AUTOSAR XML (schema 4-2-2)
package /ComponentTypes
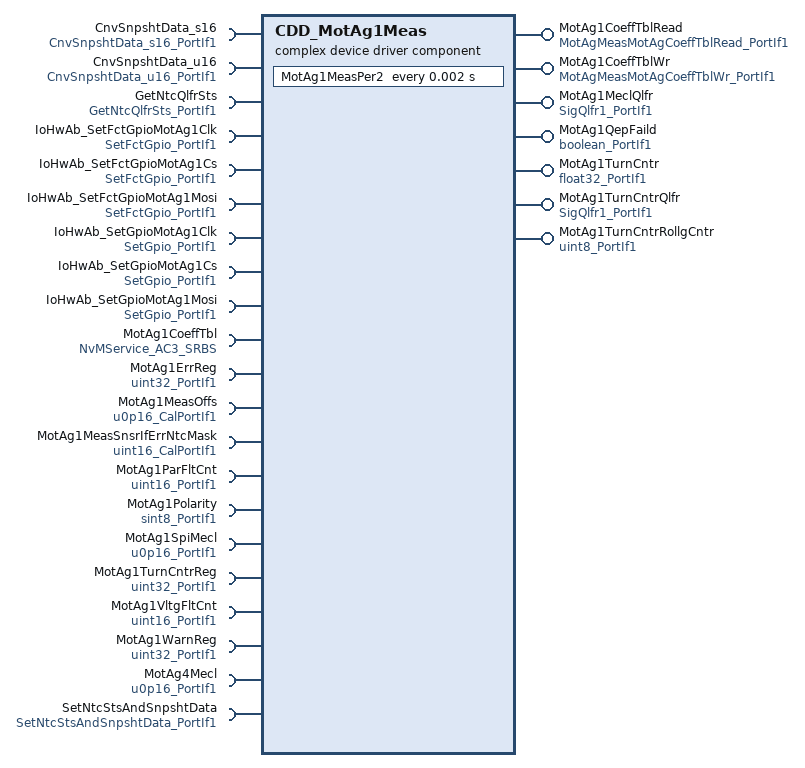
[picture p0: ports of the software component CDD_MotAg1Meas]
  complex device driver sw component type CDD_MotAg1Meas
    7 x provide port:
      MotAg1CoeffTblRead: server-com-spec{operation=Oper, queue-length=1}, provided-interface=MotAgMeasMotAgCoeffTblRead_PortIf1
      MotAg1CoeffTblWr: server-com-spec{operation=Oper, queue-length=1}, provided-interface=MotAgMeasMotAgCoeffTblWr_PortIf1
      MotAg1MeclQlfr: nonqueued-sender-com-spec{data-element=Val, init-value=0}, provided-interface=SigQlfr1_PortIf1
      MotAg1QepFaild: nonqueued-sender-com-spec{data-element=Logl, init-value=0}, provided-interface=boolean_PortIf1
      MotAg1TurnCntr: nonqueued-sender-com-spec{data-element=Val, init-value=0}, provided-interface=float32_PortIf1
      MotAg1TurnCntrQlfr: nonqueued-sender-com-spec{data-element=Val, init-value=0}, provided-interface=SigQlfr1_PortIf1
      MotAg1TurnCntrRollgCntr: nonqueued-sender-com-spec{data-element=Val, init-value=0}, provided-interface=uint8_PortIf1
    21 x require port:
      CnvSnpshtData_s16: client-com-spec=Oper, required-interface=CnvSnpshtData_s16_PortIf1
      CnvSnpshtData_u16: client-com-spec=Oper, required-interface=CnvSnpshtData_u16_PortIf1
      GetNtcQlfrSts: client-com-spec=Oper, required-interface=GetNtcQlfrSts_PortIf1
      IoHwAb_SetFctGpioMotAg1Clk: client-com-spec=Oper, required-interface=SetFctGpio_PortIf1
      IoHwAb_SetFctGpioMotAg1Cs: client-com-spec=Oper, required-interface=SetFctGpio_PortIf1
      IoHwAb_SetFctGpioMotAg1Mosi: client-com-spec=Oper, required-interface=SetFctGpio_PortIf1
      IoHwAb_SetGpioMotAg1Clk: client-com-spec=Oper, required-interface=SetGpio_PortIf1
      IoHwAb_SetGpioMotAg1Cs: client-com-spec=Oper, required-interface=SetGpio_PortIf1
      IoHwAb_SetGpioMotAg1Mosi: client-com-spec=Oper, required-interface=SetGpio_PortIf1
      MotAg1CoeffTbl: required-com-specs=[EraseBlock, GetErrorStatus, InvalidateNvBlock, ReadBlock, SetRamBlockStatus, WriteBlock], required-interface=NvMService_AC3_SRBS
      MotAg1ErrReg: nonqueued-receiver-com-spec{data-element=Val, filter=data-filter-type=ALWAYS, init-value=0}, required-interface=uint32_PortIf1
      MotAg1MeasOffs: parameter-require-com-spec{init-value=32768, parameter=Val}, required-interface=u0p16_CalPortIf1
      MotAg1MeasSnsrIfErrNtcMask: parameter-require-com-spec{init-value=512, parameter=Val}, required-interface=uint16_CalPortIf1
      MotAg1ParFltCnt: nonqueued-receiver-com-spec{data-element=Val, filter=data-filter-type=ALWAYS, init-value=0}, required-interface=uint16_PortIf1
      MotAg1Polarity: nonqueued-receiver-com-spec{data-element=Val, filter=data-filter-type=ALWAYS, init-value=1}, required-interface=sint8_PortIf1
      MotAg1SpiMecl: nonqueued-receiver-com-spec{data-element=Val, filter=data-filter-type=ALWAYS, init-value=0}, required-interface=u0p16_PortIf1
      MotAg1TurnCntrReg: nonqueued-receiver-com-spec{data-element=Val, filter=data-filter-type=ALWAYS, init-value=0}, required-interface=uint32_PortIf1
      MotAg1VltgFltCnt: nonqueued-receiver-com-spec{data-element=Val, filter=data-filter-type=ALWAYS, init-value=0}, required-interface=uint16_PortIf1
      MotAg1WarnReg: nonqueued-receiver-com-spec{data-element=Val, filter=data-filter-type=ALWAYS, init-value=0}, required-interface=uint32_PortIf1
      MotAg4Mecl: nonqueued-receiver-com-spec{data-element=Val, filter=data-filter-type=ALWAYS, init-value=0}, required-interface=u0p16_PortIf1
      SetNtcStsAndSnpshtData: client-com-spec=Oper, required-interface=SetNtcStsAndSnpshtData_PortIf1
    behavior CDD_MotAg1Meas_InternalBehavior
      ar-typed-per-instance-memorys:
        27 x data, all with sw-calibration-access=READ-ONLY:
          dMotAg1MeasMotAg1Delta: type=u0p16  # Display variable holding difference between angle from QEP interface and angle from SPI bus
          dMotAg1MeasMotAg1RawAgReg: type=uint32  # Display variable for Motor Angle 1 Raw Angle Register
          dMotAg1MeasMotAg1RawErrReg: type=uint32  # Display variable for Motor Angle 1 Raw Error Register
          dMotAg1MeasMotAg1RawStsReg: type=uint32  # Display variable for Motor Angle 1 Raw status Register
          dMotAg1MeasMotAg1RawTurnCntrReg: type=uint32  # Display variable Motor Angle 1 Raw Turn Counter Register
          dMotAg1MeasMotAg1RawWarnReg: type=uint32  # Display variable for Motor Angle 1 Raw warning Register
          dMotAg1MeasMotAg1RtOffs: type=uint16  # Display variable of Motor Angle 1 Runtime Offset
          dMotAg1MeasPwrRstStsLtch: type=boolean
          MotAg1CoeffTbl: type=Ary1D_f32_26
          MotAg1CorrnTbl: type=Ary1D_sm5p12_128
          MotAg1InitOffs: type=sint32
          MotAg1InitOffsCntr: type=uint8
          MotAg1MeclRollgCntrPrev: type=uint8
          MotAg1ParFltCntNtcPrev: type=uint16
          MotAg1ParFltCntPrev: type=uint16
          MotAg1PrevSpiMecl: type=u0p16
          MotAg1PrevTCUpd: type=sint16
          MotAg1QepFaildCntr: type=uint32
          MotAg1QepFaildPrev: type=boolean
          MotAg1RawMeclPrev: type=u0p16
          MotAg1TurnCntrParFltCntNtcPrev: type=uint16
          MotAg1TurnCntrParFltCntPrev: type=uint16
          MotAg1TurnCntrPrev: type=sint16
          MotAg1TurnCntrRollgCntrPrev: type=uint8
          MotAg1VltgFltCntNtcPrev: type=uint16
          MotAg1VltgFltCntPrev: type=uint16
          MotAgMecl1Polarity: type=sint8
      operation invoked event OIT_MotAg1CoeffTblRead_Oper_MotAg1CoeffTblRead_Oper: start-on-event=MotAg1CoeffTblRead_Oper, operation=MotAg1CoeffTblRead.Oper
      operation invoked event OIT_MotAg1CoeffTblWr_Oper_MotAg1CoeffTblWr_Oper: start-on-event=MotAg1CoeffTblWr_Oper, operation=MotAg1CoeffTblWr.Oper
      init event CDD_MotAg1Meas_InitEvent: start-on-event=MotAg1MeasInit1
      timing event TMT_MotAg1MeasPer2: start-on-event=MotAg1MeasPer2, period=0.002
      port-api-options:
        enable-take-address=false, error-handling=NO-TRANSFORMER-ERROR-HANDLING, indirect-api=false, port=CnvSnpshtData_s16
        enable-take-address=false, error-handling=NO-TRANSFORMER-ERROR-HANDLING, indirect-api=false, port=CnvSnpshtData_u16
        enable-take-address=false, error-handling=NO-TRANSFORMER-ERROR-HANDLING, indirect-api=false, port=GetNtcQlfrSts
        enable-take-address=false, error-handling=NO-TRANSFORMER-ERROR-HANDLING, indirect-api=false, port=MotAg1CoeffTbl
        enable-take-address=false, error-handling=NO-TRANSFORMER-ERROR-HANDLING, indirect-api=false, port=MotAg1CoeffTblRead
        enable-take-address=false, error-handling=NO-TRANSFORMER-ERROR-HANDLING, indirect-api=false, port=MotAg1CoeffTblWr
        enable-take-address=false, error-handling=NO-TRANSFORMER-ERROR-HANDLING, indirect-api=false, port=MotAg1ErrReg
        enable-take-address=false, error-handling=NO-TRANSFORMER-ERROR-HANDLING, indirect-api=false, port=MotAg1MeasOffs
        enable-take-address=false, error-handling=NO-TRANSFORMER-ERROR-HANDLING, indirect-api=false, port=MotAg1MeasSnsrIfErrNtcMask
        enable-take-address=false, error-handling=NO-TRANSFORMER-ERROR-HANDLING, indirect-api=false, port=MotAg1MeclQlfr
        enable-take-address=false, error-handling=NO-TRANSFORMER-ERROR-HANDLING, indirect-api=false, port=MotAg1ParFltCnt
        enable-take-address=false, error-handling=NO-TRANSFORMER-ERROR-HANDLING, indirect-api=false, port=MotAg1Polarity
        enable-take-address=false, error-handling=NO-TRANSFORMER-ERROR-HANDLING, indirect-api=false, port=MotAg1QepFaild
        enable-take-address=false, error-handling=NO-TRANSFORMER-ERROR-HANDLING, indirect-api=false, port=MotAg1SpiMecl
        enable-take-address=false, error-handling=NO-TRANSFORMER-ERROR-HANDLING, indirect-api=false, port=MotAg1TurnCntr
        enable-take-address=false, error-handling=NO-TRANSFORMER-ERROR-HANDLING, indirect-api=false, port=MotAg1TurnCntrQlfr
        enable-take-address=false, error-handling=NO-TRANSFORMER-ERROR-HANDLING, indirect-api=false, port=MotAg1TurnCntrReg
        enable-take-address=false, error-handling=NO-TRANSFORMER-ERROR-HANDLING, indirect-api=false, port=MotAg1TurnCntrRollgCntr
        enable-take-address=false, error-handling=NO-TRANSFORMER-ERROR-HANDLING, indirect-api=false, port=MotAg1VltgFltCnt
        enable-take-address=false, error-handling=NO-TRANSFORMER-ERROR-HANDLING, indirect-api=false, port=MotAg1WarnReg
        enable-take-address=false, error-handling=NO-TRANSFORMER-ERROR-HANDLING, indirect-api=false, port=MotAg4Mecl
        enable-take-address=false, error-handling=NO-TRANSFORMER-ERROR-HANDLING, indirect-api=false, port=SetNtcStsAndSnpshtData
      4 x runnable:
        MotAg1CoeffTblRead_Oper
        MotAg1CoeffTblWr_Oper
          sync call SC_MotAg1CoeffTbl_SetRamBlockStatus: operation=MotAg1CoeffTbl.SetRamBlockStatus, timeout=0
        MotAg1MeasInit1
          data-receive-point-by-arguments:
            access REC_MotAg1Polarity_Val: accessed-variable=MotAg1Polarity.Val
          7 x sync call, all with timeout=0:
            SC_IoHwAb_SetFctGpioMotAg1Clk_Oper: operation=IoHwAb_SetFctGpioMotAg1Clk.Oper
            SC_IoHwAb_SetFctGpioMotAg1Cs_Oper: operation=IoHwAb_SetFctGpioMotAg1Cs.Oper
            SC_IoHwAb_SetFctGpioMotAg1Mosi_Oper: operation=IoHwAb_SetFctGpioMotAg1Mosi.Oper
            SC_IoHwAb_SetGpioMotAg1Clk_Oper: operation=IoHwAb_SetGpioMotAg1Clk.Oper
            SC_IoHwAb_SetGpioMotAg1Cs_Oper: operation=IoHwAb_SetGpioMotAg1Cs.Oper
            SC_IoHwAb_SetGpioMotAg1Mosi_Oper: operation=IoHwAb_SetGpioMotAg1Mosi.Oper
            SC_MotAg1CoeffTbl_GetErrorStatus: operation=MotAg1CoeffTbl.GetErrorStatus
        MotAg1MeasPer2
          data-receive-point-by-arguments:
            8 x access:
              REC_MotAg1ErrReg_Val: accessed-variable=MotAg1ErrReg.Val
              REC_MotAg1ParFltCnt_Val: accessed-variable=MotAg1ParFltCnt.Val
              REC_MotAg1Polarity_Val: accessed-variable=MotAg1Polarity.Val
              REC_MotAg1SpiMecl_Val: accessed-variable=MotAg1SpiMecl.Val
              REC_MotAg1TurnCntrReg_Val: accessed-variable=MotAg1TurnCntrReg.Val
              REC_MotAg1VltgFltCnt_Val: accessed-variable=MotAg1VltgFltCnt.Val
              REC_MotAg1WarnReg_Val: accessed-variable=MotAg1WarnReg.Val
              REC_MotAg4Mecl_Val: accessed-variable=MotAg4Mecl.Val
          data-send-points:
            5 x access:
              SEND_MotAg1MeclQlfr_Val: accessed-variable=MotAg1MeclQlfr.Val
              SEND_MotAg1QepFaild_Logl: accessed-variable=MotAg1QepFaild.Logl
              SEND_MotAg1TurnCntr_Val: accessed-variable=MotAg1TurnCntr.Val
              SEND_MotAg1TurnCntrQlfr_Val: accessed-variable=MotAg1TurnCntrQlfr.Val
              SEND_MotAg1TurnCntrRollgCntr_Val: accessed-variable=MotAg1TurnCntrRollgCntr.Val
          4 x sync call, all with timeout=0:
            SC_CnvSnpshtData_s16_Oper: operation=CnvSnpshtData_s16.Oper
            SC_CnvSnpshtData_u16_Oper: operation=CnvSnpshtData_u16.Oper
            SC_GetNtcQlfrSts_Oper: operation=GetNtcQlfrSts.Oper
            SC_SetNtcStsAndSnpshtData_Oper: operation=SetNtcStsAndSnpshtData.Oper
      swc service dependency NvmMotAg1CoeffTbl: assigned-datas=role-based-data-assignment={role=ramBlock, used-data-element=MotAg1CoeffTbl}, assigned-ports=role-based-port-assignment={port-prototype=MotAg1CoeffTbl, role=NvMService_AC3_SRBS}
        service-needs:
          nv block needs NvmMotAg1CoeffTbl: n-data-sets=0, ram-block-status-control=API, readonly=false, reliability=ERROR-DETECTION, resistant-to-changed-sw=true, restore-at-start=true, store-at-shutdown=true, write-only-once=false, writing-frequency=0, writing-priority=LOW
      shared-parameters:
        parameter data prototype MotAg1CoeffTblDft: sw-calibration-access=READ-WRITE, type=Ary1D_f32_26, init-value=26 x 0
  swc implementation CDD_MotAg1Meas_Implementation: behavior=CDD_MotAg1Meas_InternalBehavior
    code-descriptors:
      code Default: artifact-descriptors=autosar-engineering-object={short-label=Default, category=SWSRC}
